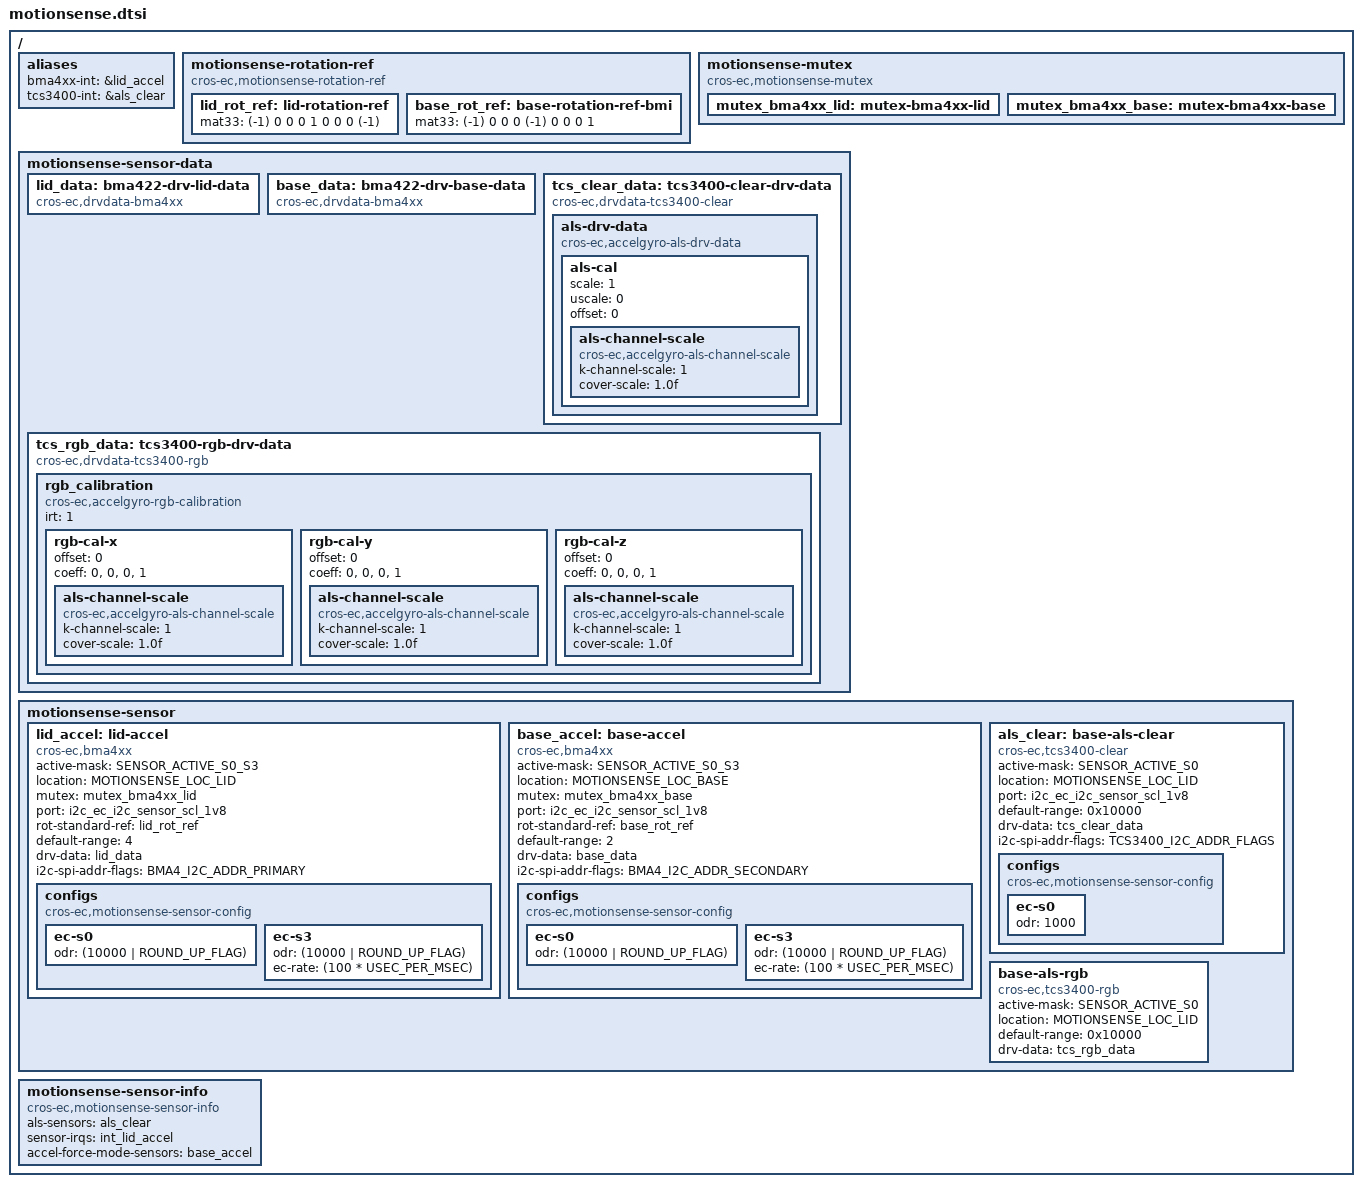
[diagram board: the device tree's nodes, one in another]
/* Copyright 2024 The ChromiumOS Authors
 * Use of this source code is governed by a BSD-style license that can be
 * found in the LICENSE file.
 *
 */

 #include <dt-bindings/motionsense/utils.h>

 / {
	aliases {
		bma4xx-int = &lid_accel;
		tcs3400-int = &als_clear;
	};

	/* Rotation matrix used by drivers. */
	motionsense-rotation-ref {
		compatible = "cros-ec,motionsense-rotation-ref";
		lid_rot_ref: lid-rotation-ref {
			mat33 = <(-1) 0 0
				 0 1 0
				 0 0 (-1)>;
		};

		base_rot_ref: base-rotation-ref-bmi {
			mat33 = <(-1) 0 0
				 0 (-1) 0
				 0 0 1>;
		};
	};

	/*
	 * Declare mutexes used by sensor drivers.
	 * A mutex node is used to create an instance of mutex_t.
	 * A mutex node is referenced by a sensor node if the
	 * corresponding sensor driver needs to use the
	 * instance of the mutex.
	 */

	motionsense-mutex {
		compatible = "cros-ec,motionsense-mutex";
		mutex_bma4xx_lid: mutex-bma4xx-lid {
		};
		mutex_bma4xx_base: mutex-bma4xx-base {
		};
	};

	/* Driver specific data */
	motionsense-sensor-data {
		lid_data: bma422-drv-lid-data {
			compatible = "cros-ec,drvdata-bma4xx";
			status = "okay";
		};
		base_data: bma422-drv-base-data {
			compatible = "cros-ec,drvdata-bma4xx";
			status = "okay";
		};
		tcs_clear_data: tcs3400-clear-drv-data {
			compatible = "cros-ec,drvdata-tcs3400-clear";
			status = "okay";

			als-drv-data {
				compatible = "cros-ec,accelgyro-als-drv-data";
				als-cal {
					scale = <1>;
					uscale = <0>;
					offset = <0>;
					als-channel-scale {
					compatible =
					"cros-ec,accelgyro-als-channel-scale";
						k-channel-scale = <1>;
						cover-scale = "1.0f";
					};
				};
			};
		};
		tcs_rgb_data: tcs3400-rgb-drv-data {
			compatible = "cros-ec,drvdata-tcs3400-rgb";
			status = "okay";

			/* node for rgb_calibration_t defined in accelgyro.h */
			rgb_calibration {
				compatible =
					"cros-ec,accelgyro-rgb-calibration";

				irt = <1>;

				rgb-cal-x {
					offset = <0>;
					coeff = "0", "0", "0", "1";
					als-channel-scale {
					compatible =
					"cros-ec,accelgyro-als-channel-scale";
						k-channel-scale = <1>;
						cover-scale = "1.0f";
					};
				};
				rgb-cal-y {
					offset = <0>;
					coeff = "0", "0", "0", "1";
					als-channel-scale {
					compatible =
					"cros-ec,accelgyro-als-channel-scale";
						k-channel-scale = <1>;
						cover-scale = "1.0f";
					};
				};
				rgb-cal-z {
					offset = <0>;
					coeff = "0", "0", "0", "1";
					als-channel-scale {
					compatible =
					"cros-ec,accelgyro-als-channel-scale";
						k-channel-scale = <1>;
						cover-scale = "1.0f";
					};
				};
			};
		};
	};

	/* List of motion sensors that create motion_sensors array. */
	motionsense-sensor {
		lid_accel: lid-accel {
			compatible = "cros-ec,bma4xx";
			status = "okay";

			active-mask = "SENSOR_ACTIVE_S0_S3";
			location = "MOTIONSENSE_LOC_LID";
			mutex = <&mutex_bma4xx_lid>;
			port = <&i2c_ec_i2c_sensor_scl_1v8>;
			rot-standard-ref = <&lid_rot_ref>;
			default-range = <4>; /* to meet CDD 7.3.1/C-1-4 reqs. */
			drv-data = <&lid_data>;
			i2c-spi-addr-flags = "BMA4_I2C_ADDR_PRIMARY";
			configs {
				compatible =
					"cros-ec,motionsense-sensor-config";
				ec-s0 {
					odr = <(10000 | ROUND_UP_FLAG)>;
				};
				ec-s3 {
					odr = <(10000 | ROUND_UP_FLAG)>;
					ec-rate = <(100 * USEC_PER_MSEC)>;
				};
			};
		};
		base_accel: base-accel {
			compatible = "cros-ec,bma4xx";
			status = "okay";

			active-mask = "SENSOR_ACTIVE_S0_S3";
			location = "MOTIONSENSE_LOC_BASE";
			mutex = <&mutex_bma4xx_base>;
			port = <&i2c_ec_i2c_sensor_scl_1v8>;
			rot-standard-ref = <&base_rot_ref>;
			default-range = <2>;
			drv-data = <&base_data>;
			i2c-spi-addr-flags = "BMA4_I2C_ADDR_SECONDARY";
			configs {
				compatible =
					"cros-ec,motionsense-sensor-config";
				ec-s0 {
					odr = <(10000 | ROUND_UP_FLAG)>;
				};
				ec-s3 {
					odr = <(10000 | ROUND_UP_FLAG)>;
					ec-rate = <(100 * USEC_PER_MSEC)>;
				};
			};
		};
		als_clear: base-als-clear {
			compatible = "cros-ec,tcs3400-clear";
			status = "okay";

			active-mask = "SENSOR_ACTIVE_S0";
			location = "MOTIONSENSE_LOC_LID";
			port = <&i2c_ec_i2c_sensor_scl_1v8>;
			default-range = <0x10000>;
			drv-data = <&tcs_clear_data>;
			i2c-spi-addr-flags = "TCS3400_I2C_ADDR_FLAGS";
			configs {
				compatible =
					"cros-ec,motionsense-sensor-config";
				ec-s0 {
					/* Run ALS sensor in S0 */
					odr = <1000>;
				};
			};
		};

		base-als-rgb {
			compatible = "cros-ec,tcs3400-rgb";
			status = "okay";

			active-mask = "SENSOR_ACTIVE_S0";
			location = "MOTIONSENSE_LOC_LID";
			default-range = <0x10000>; /* scale = 1x, uscale = 0 */
			drv-data = <&tcs_rgb_data>;
		};
	};

	/* High level description info */
	motionsense-sensor-info {
		compatible = "cros-ec,motionsense-sensor-info";

		/* list of entries for motion_als_sensors */
		als-sensors = <&als_clear>;

		/*
		 * List of GPIO interrupts that have to be enabled at initial
		 * stage.
		 */
		sensor-irqs = <&int_lid_accel>;
		/* list of sensors in force mode */
		accel-force-mode-sensors = <&base_accel>;
	};
};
